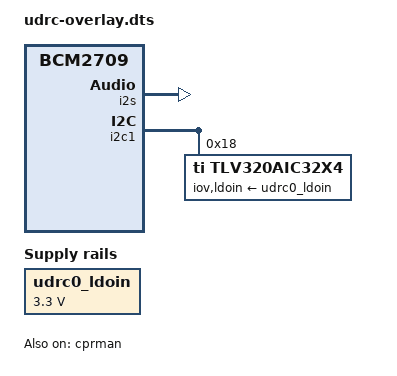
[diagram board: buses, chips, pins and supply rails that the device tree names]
#include <dt-bindings/clock/bcm2835.h>
/*
 * Device tree overlay for the Universal Digital Radio Controller
 */

/dts-v1/;
/plugin/;

/ {
    compatible = "brcm,bcm2835", "brcm,bcm2836", "brcm,bcm2708", "brcm,bcm2709";
    fragment@0 {
        target = <&i2s>;
        __overlay__ {
            clocks = <&cprman BCM2835_CLOCK_PCM>;
            clock-names = "pcm";
            status = "okay";
        };
    };

    fragment@1 {
        target-path = "/";
        __overlay__ {
            regulators {
                compatible = "simple-bus";
                #address-cells = <1>;
                #size-cells = <0>;

                udrc0_ldoin: udrc0_ldoin {
                    compatible = "regulator-fixed";
                    regulator-name = "ldoin";
                    regulator-min-microvolt = <3300000>;
                    regulator-max-microvolt = <3300000>;
                    regulator-always-on;
                };
            };
        };
    };

    fragment@2 {
        target = <&i2c1>;
        __overlay__ {
            #address-cells = <1>;
            #size-cells = <0>;
            status = "okay";

            tlv320aic32x4: tlv320aic32x4@18 {
                compatible = "ti,tlv320aic32x4";
                reg = <0x18>;
                status = "okay";

                clocks = <&cprman BCM2835_CLOCK_GP0>;
                clock-names = "mclk";
                assigned-clocks = <&cprman BCM2835_CLOCK_GP0>;
                assigned-clock-rates = <25000000>;
                pinctrl-names = "default";
                pinctrl-0 = <&gpclk0_pin>;

                iov-supply = <&udrc0_ldoin>;
                ldoin-supply = <&udrc0_ldoin>;

				ti,hp-ldoin-powered;
				ti,lo-ldoin-powered;

				ti,avdd-weak-disable;
				
				ti,common-mode-microvolt = <1650000>;
            };
        };
    };

    fragment@3 {
		target = <&sound>;
		__overlay__ {
			compatible = "nwdr,udrc";
			i2s-controller = <&i2s>;
			codec-device = <&tlv320aic32x4>;
			status = "okay";
		};
	};
	
	fragment@4 {
        target = <&gpio>;
        __overlay__ {
             gpclk0_pin: gpclk0_pin {
            	brcm,pins = <4>;
            	brcm,function = <4>;
            };
        };
    };

    fragment@5 {
        target = <&cprman>;
        __overlay__ {
            status = "okay";
        };
    };
    
    fragment@6 {
    	target = <&sdhost>;
    	__overlay__ {
    		clocks = <&cprman BCM2835_CLOCK_EMMC>;
    	};
    };
};
